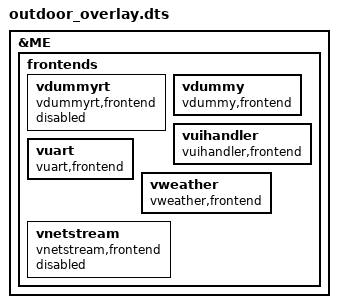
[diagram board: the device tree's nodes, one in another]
/include/ "so3virt.dts"

&ME {
    
    frontends {
    
        vdummyrt {
            compatible = "vdummyrt,frontend";
            status = "disabled";
        };

        vdummy {
            compatible = "vdummy,frontend";
            status = "ok";
        };

        vuihandler {
            compatible = "vuihandler,frontend";
            status = "ok";
        };

        vuart {
            compatible = "vuart,frontend";
            status = "ok";
        };

        vweather {
            compatible = "vweather,frontend";
            status = "ok";
        };

        vnetstream {
            compatible = "vnetstream,frontend";
            status = "disabled";
        };
    };
};
